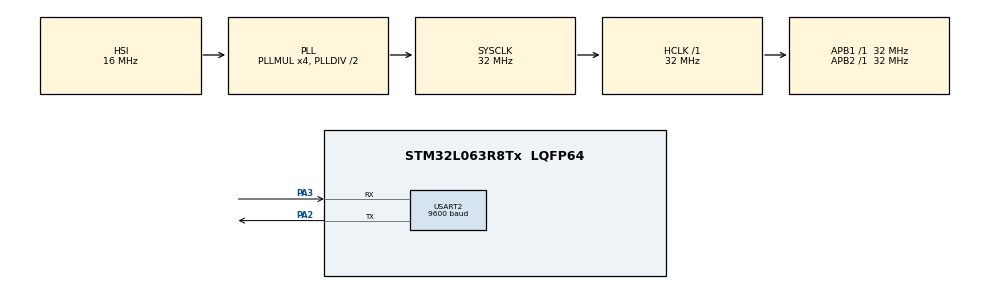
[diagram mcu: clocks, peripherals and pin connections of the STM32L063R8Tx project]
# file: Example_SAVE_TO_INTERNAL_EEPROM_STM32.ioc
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ADC.ClockPrescaler=ADC_CLOCK_SYNC_PCLK_DIV2
ADC.ContinuousConvMode=DISABLE
ADC.DMAContinuousRequests=DISABLE
ADC.DataAlign=ADC_DATAALIGN_RIGHT
ADC.DiscontinuousConvMode=ENABLE
ADC.EOCSelection=ADC_EOC_SEQ_CONV
ADC.EnableAnalogWatchDog=false
ADC.ExternalTrigConv=ADC_SOFTWARE_START
ADC.ExternalTrigConvEdge=ADC_EXTERNALTRIGCONVEDGE_NONE
ADC.LowPowerAutoPowerOff=ENABLE
ADC.LowPowerAutoWait=ENABLE
ADC.LowPowerFrequencyMode=DISABLE
ADC.Overrun=ADC_OVR_DATA_PRESERVED
ADC.OversamplingMode=DISABLE
ADC.Resolution=ADC_RESOLUTION_12B
ADC.SamplingTime=ADC_SAMPLETIME_79CYCLES_5
ADC.ScanConvMode=ADC_SCAN_DIRECTION_FORWARD
Mcu.Family=STM32L0
Mcu.Name=STM32L063R8Tx
Mcu.Package=LQFP64
NVIC.USART2_IRQn=true\:0\:0\:false\:false\:true\:true
PA2.Mode=Asynchronous
PA2.Signal=USART2_TX
PA3.Mode=Asynchronous
PA3.Signal=USART2_RX
ProjectManager.HeapSize=0x200
ProjectManager.StackSize=0x400
ProjectManager.TargetToolchain=TrueSTUDIO
RCC.ADCFreq_Value=16000000
RCC.AHBFreq_Value=32000000
RCC.APB1Freq_Value=32000000
RCC.APB1TimFreq_Value=32000000
RCC.APB2Freq_Value=32000000
RCC.APB2TimFreq_Value=32000000
RCC.HCLKFreq_Value=32000000
RCC.HSE_VALUE=8000000
RCC.HSI16_VALUE=16000000
RCC.HSI48MClockSelection=RCC_USBCLKSOURCE_HSI48
RCC.HSI48_VALUE=48000000
RCC.HSI_VALUE=16000000
RCC.LSE_VALUE=32768
RCC.MSI_VALUE=2097000
RCC.PLLMUL=RCC_PLLMUL_4
RCC.SYSCLKFreq_VALUE=32000000
RCC.SYSCLKSource=RCC_SYSCLKSOURCE_PLLCLK
RCC.VCOOutputFreq_Value=64000000
RTC.Alarm-Alarm\ A=RTC_ALARM_A
RTC.Alarm_B-Alarm\ B=RTC_ALARM_B
USART2.BaudRate=9600
USART2.VirtualMode-Asynchronous=VM_ASYNC
USART2.WordLength=WORDLENGTH_8B
VP_ADC_TempSens_Input.Mode=IN-TempSens
VP_ADC_Vref_Input.Mode=IN-Vrefint
VP_RTC_VS_RTC_Activate.Mode=RTC_Enabled
VP_RTC_VS_RTC_Alarm_A_Intern.Mode=Alarm A
VP_RTC_VS_RTC_Alarm_B_Intern.Mode=Alarm B
VP_RTC_VS_RTC_Calendar.Mode=RTC_Calendar
VP_RTC_VS_RTC_WakeUp_intern.Mode=WakeUp
board=Example_SAVE_TO_INTERNAL_EEPROM_STM32

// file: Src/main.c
/**
  ******************************************************************************
  * @file           : main.c
  * @brief          : Main program body
  ******************************************************************************
  ** This notice applies to any and all portions of this file
  * that are not between comment pairs USER CODE BEGIN and
  * USER CODE END. Other portions of this file, whether
  * inserted by the user or by software development tools
  * are owned by their respective copyright owners.
  *
  * COPYRIGHT(c) 2018 STMicroelectronics
  *
  * Redistribution and use in source and binary forms, with or without modification,
  * are permitted provided that the following conditions are met:
  *   1. Redistributions of source code must retain the above copyright notice,
  *      this list of conditions and the following disclaimer.
  *   2. Redistributions in binary form must reproduce the above copyright notice,
  *      this list of conditions and the following disclaimer in the documentation
  *      and/or other materials provided with the distribution.
  *   3. Neither the name of STMicroelectronics nor the names of its contributors
  *      may be used to endorse or promote products derived from this software
  *      without specific prior written permission.
  *
  * THIS SOFTWARE IS PROVIDED BY THE COPYRIGHT HOLDERS AND CONTRIBUTORS "AS IS"
  * AND ANY EXPRESS OR IMPLIED WARRANTIES, INCLUDING, BUT NOT LIMITED TO, THE
  * IMPLIED WARRANTIES OF MERCHANTABILITY AND FITNESS FOR A PARTICULAR PURPOSE ARE
  * DISCLAIMED. IN NO EVENT SHALL THE COPYRIGHT HOLDER OR CONTRIBUTORS BE LIABLE
  * FOR ANY DIRECT, INDIRECT, INCIDENTAL, SPECIAL, EXEMPLARY, OR CONSEQUENTIAL
  * DAMAGES (INCLUDING, BUT NOT LIMITED TO, PROCUREMENT OF SUBSTITUTE GOODS OR
  * SERVICES; LOSS OF USE, DATA, OR PROFITS; OR BUSINESS INTERRUPTION) HOWEVER
  * CAUSED AND ON ANY THEORY OF LIABILITY, WHETHER IN CONTRACT, STRICT LIABILITY,
  * OR TORT (INCLUDING NEGLIGENCE OR OTHERWISE) ARISING IN ANY WAY OUT OF THE USE
  * OF THIS SOFTWARE, EVEN IF ADVISED OF THE POSSIBILITY OF SUCH DAMAGE.
  *
  ******************************************************************************
  */
#include "main.h"
#include "stm32l0xx_hal.h"
#include "adc.h"
#include "rtc.h"
#include "usart.h"
#include "gpio.h"

/* USER CODE BEGIN Includes */
#include "SAVE_TO_INTERNAL_EEPROM/save_to_internal_eeprom.h"
/* USER CODE END Includes */

/* USER CODE BEGIN PV */
/* Private variables ---------------------------------------------------------*/
struct {
	uint8_t counter;
	uint8_t name[64];
}data_s;

uint16_t size;
uint8_t Data[100];
/* USER CODE END PV */

void SystemClock_Config(void);

/* USER CODE BEGIN PFP */
/* Private function prototypes -----------------------------------------------*/

/* USER CODE END PFP */

int main(void)
{

  /* MCU Configuration----------------------------------------------------------*/

  /* Reset of all peripherals, Initializes the Flash interface and the Systick. */
  HAL_Init();

  /* Configure the system clock */
  SystemClock_Config();

  /* Initialize all configured peripherals */
  MX_GPIO_Init();
  MX_USART2_UART_Init();
  MX_RTC_Init();
  MX_ADC_Init();
  /* USER CODE BEGIN 2 */
  READ_INTERNAL_EEPROM(&data_s,sizeof(data_s),0x00);
  size = sprintf((char *)Data,"data_s.counter=%d, data.name=%s\n",data_s.counter,data_s.name);
  HAL_UART_Transmit(&huart2,Data,size,500);
  /* USER CODE END 2 */

  /* Infinite loop */
  while (1)
  {

  /* USER CODE BEGIN 3 */
	  data_s.counter ++;
	  WRITE_INTERNAL_EEPROM(&data_s,sizeof(data_s),0x00);
	  HAL_Delay(1000);
  }
  /* USER CODE END 3 */

}

void SystemClock_Config(void)
{

  RCC_OscInitTypeDef RCC_OscInitStruct;
  RCC_ClkInitTypeDef RCC_ClkInitStruct;
  RCC_PeriphCLKInitTypeDef PeriphClkInit;

    /**Configure the main internal regulator output voltage
    */
  __HAL_PWR_VOLTAGESCALING_CONFIG(PWR_REGULATOR_VOLTAGE_SCALE1);

    /**Initializes the CPU, AHB and APB busses clocks
    */
  RCC_OscInitStruct.OscillatorType = RCC_OSCILLATORTYPE_HSI|RCC_OSCILLATORTYPE_LSI;
  RCC_OscInitStruct.HSIState = RCC_HSI_ON;
  RCC_OscInitStruct.HSICalibrationValue = 16;
  RCC_OscInitStruct.LSIState = RCC_LSI_ON;
  RCC_OscInitStruct.PLL.PLLState = RCC_PLL_ON;
  RCC_OscInitStruct.PLL.PLLSource = RCC_PLLSOURCE_HSI;
  RCC_OscInitStruct.PLL.PLLMUL = RCC_PLLMUL_4;
  RCC_OscInitStruct.PLL.PLLDIV = RCC_PLLDIV_2;
  if (HAL_RCC_OscConfig(&RCC_OscInitStruct) != HAL_OK)
  {
    _Error_Handler(__FILE__, __LINE__);
  }

    /**Initializes the CPU, AHB and APB busses clocks
    */
  RCC_ClkInitStruct.ClockType = RCC_CLOCKTYPE_HCLK|RCC_CLOCKTYPE_SYSCLK
                              |RCC_CLOCKTYPE_PCLK1|RCC_CLOCKTYPE_PCLK2;
  RCC_ClkInitStruct.SYSCLKSource = RCC_SYSCLKSOURCE_PLLCLK;
  RCC_ClkInitStruct.AHBCLKDivider = RCC_SYSCLK_DIV1;
  RCC_ClkInitStruct.APB1CLKDivider = RCC_HCLK_DIV1;
  RCC_ClkInitStruct.APB2CLKDivider = RCC_HCLK_DIV1;

  if (HAL_RCC_ClockConfig(&RCC_ClkInitStruct, FLASH_LATENCY_1) != HAL_OK)
  {
    _Error_Handler(__FILE__, __LINE__);
  }

  PeriphClkInit.PeriphClockSelection = RCC_PERIPHCLK_USART2|RCC_PERIPHCLK_RTC;
  PeriphClkInit.Usart2ClockSelection = RCC_USART2CLKSOURCE_PCLK1;
  PeriphClkInit.RTCClockSelection = RCC_RTCCLKSOURCE_LSI;
  if (HAL_RCCEx_PeriphCLKConfig(&PeriphClkInit) != HAL_OK)
  {
    _Error_Handler(__FILE__, __LINE__);
  }

    /**Configure the Systick interrupt time
    */
  HAL_SYSTICK_Config(HAL_RCC_GetHCLKFreq()/1000);

    /**Configure the Systick
    */
  HAL_SYSTICK_CLKSourceConfig(SYSTICK_CLKSOURCE_HCLK);

  /* SysTick_IRQn interrupt configuration */
  HAL_NVIC_SetPriority(SysTick_IRQn, 0, 0);
}

void _Error_Handler(char *file, int line)
{
  while(1)
  {
  }
}

/************************ (C) COPYRIGHT STMicroelectronics *****END OF FILE****/
